VERSION "HIPBNYYYYYYYYYYYYYYYYYYYYYYYYYYYYYYYYYYYYY/4/%%%/4/'%**4YYY///"

NS_ :

BS_:

BU_: TAG ADS

BO_ 766 SCU_Control: 8 Vector__XXX
 SG_ SCU_RWA_Req : 0|12@1- (0.001,0) [-2.048|2.047] "rad" Vector__XXX

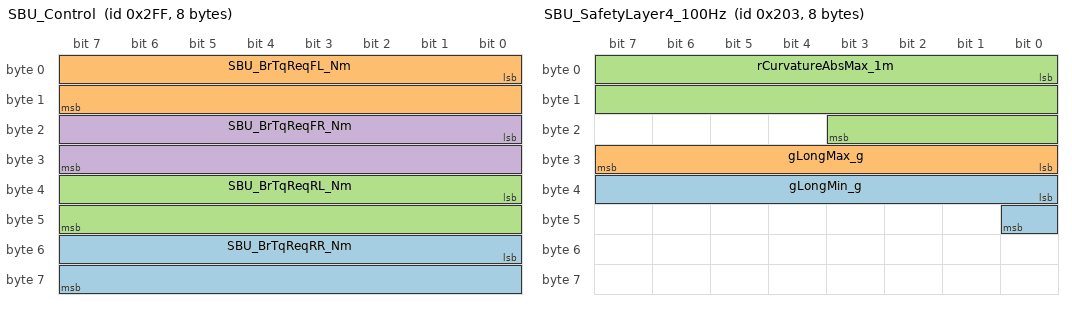
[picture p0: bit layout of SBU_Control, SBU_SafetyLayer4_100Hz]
BO_ 767 SBU_Control: 8 Vector__XXX
 SG_ SBU_BrTqReqRR_Nm : 48|16@1+ (1,0) [0|65535] "Nm" Vector__XXX
 SG_ SBU_BrTqReqFL_Nm : 0|16@1+ (1,0) [0|65535] "Nm" Vector__XXX
 SG_ SBU_BrTqReqRL_Nm : 32|16@1+ (1,0) [0|65535] "Nm" Vector__XXX
 SG_ SBU_BrTqReqFR_Nm : 16|16@1+ (1,0) [0|65535] "Nm" Vector__XXX

BO_ 515 SBU_SafetyLayer4_100Hz: 8 Vector__XXX
 SG_ gLongMin_g : 32|9@1+ (0.01,-5.11) [-5.11|0] "g" Vector__XXX
 SG_ gLongMax_g : 24|8@1+ (0.01,0) [0|2.55] "g" Vector__XXX
 SG_ rCurvatureAbsMax_1m : 0|20@1+ (1E-006,0) [0|1.048575] "1/m" Vector__XXX

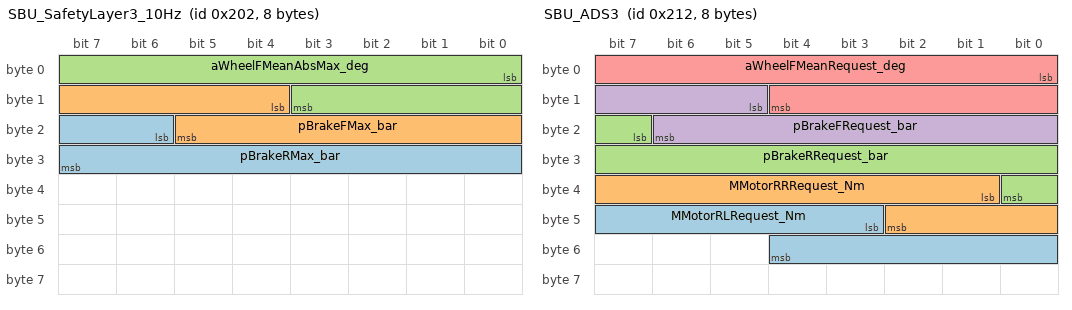
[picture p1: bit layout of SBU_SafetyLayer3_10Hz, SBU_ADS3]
BO_ 514 SBU_SafetyLayer3_10Hz: 8 Vector__XXX
 SG_ pBrakeRMax_bar : 22|10@1+ (0.1,0) [0|102.3] "bar" Vector__XXX
 SG_ pBrakeFMax_bar : 12|10@1+ (0.1,0) [0|102.3] "bar" Vector__XXX
 SG_ aWheelFMeanAbsMax_deg : 0|12@1+ (0.01,0) [0|40.95] "deg" Vector__XXX

BO_ 530 SBU_ADS3: 8 Vector__XXX
 SG_ MMotorRLRequest_Nm : 43|10@1- (1,0) [-512|511] "Nm" Vector__XXX
 SG_ MMotorRRRequest_Nm : 33|10@1- (1,0) [-512|511] "Nm" Vector__XXX
 SG_ pBrakeRRequest_bar : 23|10@1+ (0.1,0) [0|102.3] "bar" Vector__XXX
 SG_ pBrakeFRequest_bar : 13|10@1+ (0.1,0) [0|102.3] "bar" Vector__XXX
 SG_ aWheelFMeanRequest_deg : 0|13@1- (0.01,0) [-40.96|40.95] "deg" Vector__XXX

BO_ 529 SBU_ADS2: 8 Vector__XXX
 SG_ gLongRequest_g : 21|10@1- (0.01,0) [-5.12|5.11] "g" Vector__XXX
 SG_ rCurvatureRequest_1m : 0|21@1- (1E-006,0) [-1.048576|1.048575] "1/m" Vector__XXX

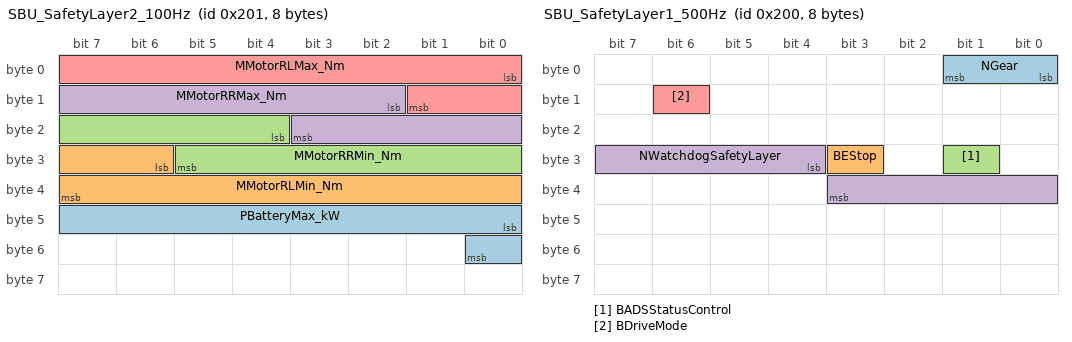
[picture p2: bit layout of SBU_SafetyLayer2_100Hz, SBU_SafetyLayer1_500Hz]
BO_ 513 SBU_SafetyLayer2_100Hz: 8 Vector__XXX
 SG_ PBatteryMax_kW : 40|9@1+ (1,0) [0|511] "kW" Vector__XXX
 SG_ MMotorRLMin_Nm : 30|10@1- (1,0) [-512|511] "Nm" Vector__XXX
 SG_ MMotorRRMin_Nm : 20|10@1- (1,0) [-512|511] "Nm" Vector__XXX
 SG_ MMotorRRMax_Nm : 10|10@1- (1,0) [-512|511] "Nm" Vector__XXX
 SG_ MMotorRLMax_Nm : 0|10@1- (1,0) [-512|511] "Nm" Vector__XXX

BO_ 512 SBU_SafetyLayer1_500Hz: 8 Vector__XXX
 SG_ NGear : 0|2@1+ (1,0) [0|3] "" Vector__XXX
 SG_ BEStop : 27|1@1+ (1,0) [0|1] "" Vector__XXX
 SG_ BADSStatusControl : 25|1@1+ (1,0) [0|3] "" Vector__XXX
 SG_ NWatchdogSafetyLayer : 28|8@1+ (1,0) [0|255] "" Vector__XXX
 SG_ BDriveMode : 14|1@1+ (1,0) [0|1] "" Vector__XXX

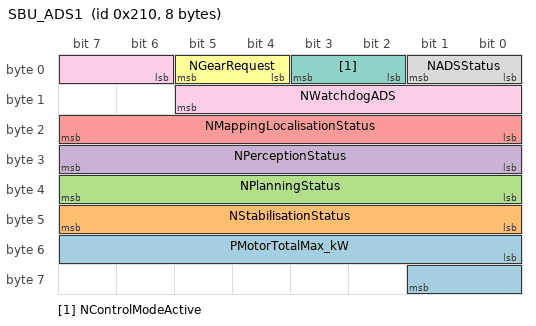
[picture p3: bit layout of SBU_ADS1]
BO_ 528 SBU_ADS1: 8 TAG
 SG_ PMotorTotalMax_kW : 48|10@1+ (1,0) [0|1023] "kW" Vector__XXX
 SG_ NStabilisationStatus : 40|8@1- (1,0) [-128|127] "" Vector__XXX
 SG_ NPlanningStatus : 32|8@1- (1,0) [-128|127] "" Vector__XXX
 SG_ NPerceptionStatus : 24|8@1- (1,0) [-128|127] "" Vector__XXX
 SG_ NMappingLocalisationStatus : 16|8@1- (1,0) [-128|127] "" Vector__XXX
 SG_ NGearRequest : 4|2@1+ (1,0) [0|3] "" Vector__XXX
 SG_ NControlModeActive : 2|2@1+ (1,0) [0|3] "" Vector__XXX
 SG_ NADSStatus : 0|2@1+ (1,0) [0|3] "" Vector__XXX
 SG_ NWatchdogADS : 6|8@1+ (1,0) [0|255] "" Vector__XXX

BA_DEF_ BO_  "GenMsgCycleTime" INT 1 1000;
BA_DEF_  "BusType" STRING ;
BA_DEF_DEF_  "GenMsgCycleTime" 100;
BA_DEF_DEF_  "BusType" "CAN";
BA_ "GenMsgCycleTime" BO_ 766 4;
BA_ "GenMsgCycleTime" BO_ 767 4;
